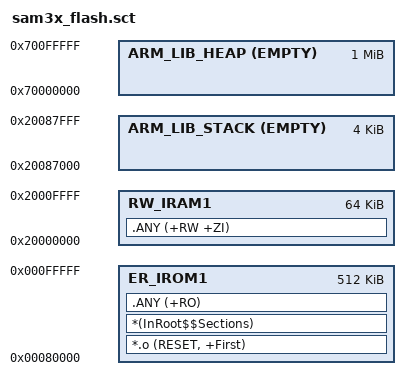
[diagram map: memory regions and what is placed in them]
;****************************************************************
;* SAM3X linker scatter file (running code from internal FLASH) *
;****************************************************************

LR_IROM1 0x00080000 0x80000
{
   ER_IROM1 0x00080000 0x80000
   {
      *.o (RESET, +First)
      *(InRoot$$Sections)
      .ANY (+RO)
   }
   
   RW_IRAM1 0x20000000 0x10000
   { 
      .ANY (+RW +ZI)
   }
   
   ARM_LIB_STACK 0x20088000 EMPTY -0x1000
   {
   }
   
   ARM_LIB_HEAP 0x70000000 EMPTY 0x100000
   {
   }
}
